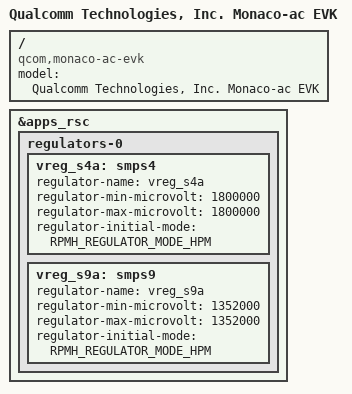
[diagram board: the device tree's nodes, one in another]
// SPDX-License-Identifier: BSD-3-Clause
/*
 * Copyright (c) Qualcomm Technologies, Inc. and/or its subsidiaries.
 */

/dts-v1/;

#include "monaco-evk-common.dtsi"

/ {
	model = "Qualcomm Technologies, Inc. Monaco-ac EVK";
	compatible = "qcom,monaco-ac-evk", "qcom,qcs8300";
};

&apps_rsc {
	regulators-0 {
		vreg_s4a: smps4 {
			regulator-name = "vreg_s4a";
			regulator-min-microvolt = <1800000>;
			regulator-max-microvolt = <1800000>;
			regulator-initial-mode = <RPMH_REGULATOR_MODE_HPM>;
		};

		vreg_s9a: smps9 {
			regulator-name = "vreg_s9a";
			regulator-min-microvolt = <1352000>;
			regulator-max-microvolt = <1352000>;
			regulator-initial-mode = <RPMH_REGULATOR_MODE_HPM>;
		};
	};
};
